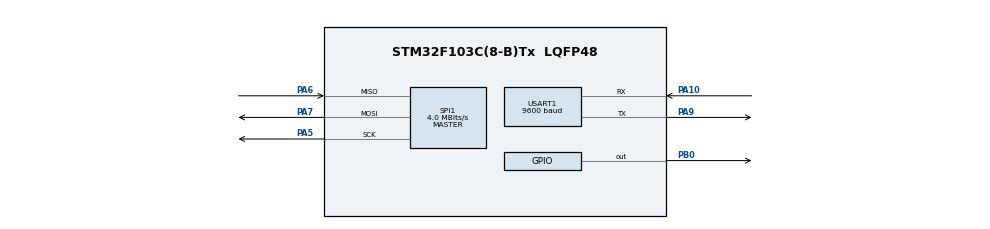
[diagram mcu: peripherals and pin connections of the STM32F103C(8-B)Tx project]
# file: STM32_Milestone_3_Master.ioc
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Mcu.Family=STM32F1
Mcu.Name=STM32F103C(8-B)Tx
Mcu.Package=LQFP48
NVIC.PriorityGroup=NVIC_PRIORITYGROUP_4
PA10.Mode=Asynchronous
PA10.Signal=USART1_RX
PA5.Mode=Full_Duplex_Master
PA5.Signal=SPI1_SCK
PA6.Mode=Full_Duplex_Master
PA6.Signal=SPI1_MISO
PA7.Mode=Full_Duplex_Master
PA7.Signal=SPI1_MOSI
PA9.Mode=Asynchronous
PA9.Signal=USART1_TX
PB0.Signal=GPIO_Output
ProjectManager.HeapSize=0x200
ProjectManager.StackSize=0x400
ProjectManager.TargetToolchain=STM32CubeIDE
RCC.APB1Freq_Value=8000000
RCC.APB2Freq_Value=8000000
SPI1.CalculateBaudRate=4.0 MBits/s
SPI1.Direction=SPI_DIRECTION_2LINES
SPI1.Mode=SPI_MODE_MASTER
SPI1.VirtualType=VM_MASTER
USART1.BaudRate=9600
USART1.VirtualMode=VM_ASYNC
VP_SYS_VS_ND.Mode=No_Debug
board=custom

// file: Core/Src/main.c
/* USER CODE BEGIN Header */
/**
  ******************************************************************************
  * @file           : main.c
  * @brief          : Main program body
  ******************************************************************************
  * @attention
  *
  * Copyright (c) 2026 STMicroelectronics.
  * All rights reserved.
  *
  * This software is licensed under terms that can be found in the LICENSE file
  * in the root directory of this software component.
  * If no LICENSE file comes with this software, it is provided AS-IS.
  *
  ******************************************************************************
  */
/* USER CODE END Header */
#include "main.h"
#include <stdio.h>
#include <string.h>

SPI_HandleTypeDef hspi1;

UART_HandleTypeDef huart1;

/* USER CODE BEGIN PV */
uint8_t rx_byte;
uint8_t case_number;
uint16_t case_id;

uint8_t tx_id[2];
uint8_t dummy_rx_id[2];      /* discarded bytes echoed by Slave during Cycle 1 */

uint8_t dummy_tx[3] = {0x00, 0x00, 0x00};
uint8_t rx_data[3];

uint16_t voltage_x10;
uint16_t wheel_speed;

char message[100];
/* USER CODE END PV */

void SystemClock_Config(void);
static void MX_GPIO_Init(void);
static void MX_SPI1_Init(void);
static void MX_USART1_UART_Init(void);

int main(void)
{

  /* MCU Configuration--------------------------------------------------------*/

  /* Reset of all peripherals, Initializes the Flash interface and the Systick. */
  HAL_Init();

  /* Configure the system clock */
  SystemClock_Config();

  /* Initialize all configured peripherals */
  MX_GPIO_Init();
  MX_SPI1_Init();
  MX_USART1_UART_Init();
  /* USER CODE BEGIN 2 */
  HAL_GPIO_WritePin(GPIOB, GPIO_PIN_0, GPIO_PIN_SET);
  /* USER CODE END 2 */

  /* Infinite loop */
  /* USER CODE BEGIN WHILE */
  while (1)
  {
      /* Ask user for Case ID */
      char prompt[] = "Enter Case ID (1-5):\r\n";

      HAL_UART_Transmit(
          &huart1,
          (uint8_t *)prompt,
          strlen(prompt),
          HAL_MAX_DELAY
      );

      /* Wait for one character from Virtual Terminal */
      HAL_UART_Receive(
          &huart1,
          &rx_byte,
          1,
          HAL_MAX_DELAY
      );

      if (rx_byte >= '1' && rx_byte <= '5')
      {
          case_number = rx_byte - '0';
          case_id = 0x1000 + case_number;

          tx_id[0] = (case_id >> 8) & 0xFF;
          tx_id[1] = case_id & 0xFF;

          /* -------- Cycle 1: send Case ID to Slave -------- */

          HAL_GPIO_WritePin(
              GPIOB,
              GPIO_PIN_0,
              GPIO_PIN_RESET
          );

          HAL_SPI_TransmitReceive(
              &hspi1,
              tx_id,
              dummy_rx_id,
              2,
              HAL_MAX_DELAY
          );

          HAL_Delay(2);

          /* -------- Cycle 2: receive 24-bit response from Slave -------- */

          HAL_SPI_TransmitReceive(
              &hspi1,
              dummy_tx,
              rx_data,
              3,
              HAL_MAX_DELAY
          );

          HAL_GPIO_WritePin(
              GPIOB,
              GPIO_PIN_0,
              GPIO_PIN_SET
          );

          uint32_t received_message =
              ((uint32_t)rx_data[0] << 16) |
              ((uint32_t)rx_data[1] << 8) |
              rx_data[2];

          voltage_x10 =
              (received_message >> 12) & 0xFFF;

          wheel_speed =
              received_message & 0xFFF;
          sprintf(message, "RAW: %02X %02X %02X\r\n", rx_data[0], rx_data[1], rx_data[2]);
          HAL_UART_Transmit(&huart1, (uint8_t*)message, strlen(message), HAL_MAX_DELAY);
          sprintf(
              message,
              "Case %d -> Voltage = %u.%u V | Wheel Speed = %u km/h\r\n",
              case_number,
              voltage_x10 / 10,
              voltage_x10 % 10,
              wheel_speed
          );

          HAL_UART_Transmit(
              &huart1,
              (uint8_t *)message,
              strlen(message),
              HAL_MAX_DELAY
          );
      }
  }
  /* USER CODE END 3 */
}

void SystemClock_Config(void)
{
  RCC_OscInitTypeDef RCC_OscInitStruct = {0};
  RCC_ClkInitTypeDef RCC_ClkInitStruct = {0};

  RCC_OscInitStruct.OscillatorType = RCC_OSCILLATORTYPE_HSI;
  RCC_OscInitStruct.HSIState = RCC_HSI_ON;
  RCC_OscInitStruct.HSICalibrationValue = RCC_HSICALIBRATION_DEFAULT;
  RCC_OscInitStruct.PLL.PLLState = RCC_PLL_NONE;
  if (HAL_RCC_OscConfig(&RCC_OscInitStruct) != HAL_OK)
  {
    Error_Handler();
  }

  RCC_ClkInitStruct.ClockType = RCC_CLOCKTYPE_HCLK|RCC_CLOCKTYPE_SYSCLK
                              |RCC_CLOCKTYPE_PCLK1|RCC_CLOCKTYPE_PCLK2;
  RCC_ClkInitStruct.SYSCLKSource = RCC_SYSCLKSOURCE_HSI;
  RCC_ClkInitStruct.AHBCLKDivider = RCC_SYSCLK_DIV1;
  RCC_ClkInitStruct.APB1CLKDivider = RCC_HCLK_DIV1;
  RCC_ClkInitStruct.APB2CLKDivider = RCC_HCLK_DIV1;

  if (HAL_RCC_ClockConfig(&RCC_ClkInitStruct, FLASH_LATENCY_0) != HAL_OK)
  {
    Error_Handler();
  }
}

static void MX_SPI1_Init(void)
{

  /* SPI1 parameter configuration*/
  hspi1.Instance = SPI1;
  hspi1.Init.Mode = SPI_MODE_MASTER;
  hspi1.Init.Direction = SPI_DIRECTION_2LINES;
  hspi1.Init.DataSize = SPI_DATASIZE_8BIT;
  hspi1.Init.CLKPolarity = SPI_POLARITY_LOW;
  hspi1.Init.CLKPhase = SPI_PHASE_1EDGE;
  hspi1.Init.NSS = SPI_NSS_SOFT;
  hspi1.Init.BaudRatePrescaler = SPI_BAUDRATEPRESCALER_256;
  hspi1.Init.FirstBit = SPI_FIRSTBIT_MSB;
  hspi1.Init.TIMode = SPI_TIMODE_DISABLE;
  hspi1.Init.CRCCalculation = SPI_CRCCALCULATION_DISABLE;
  hspi1.Init.CRCPolynomial = 10;
  if (HAL_SPI_Init(&hspi1) != HAL_OK)
  {
    Error_Handler();
  }

}

static void MX_USART1_UART_Init(void)
{

  huart1.Instance = USART1;
  huart1.Init.BaudRate = 9600;
  huart1.Init.WordLength = UART_WORDLENGTH_8B;
  huart1.Init.StopBits = UART_STOPBITS_1;
  huart1.Init.Parity = UART_PARITY_NONE;
  huart1.Init.Mode = UART_MODE_TX_RX;
  huart1.Init.HwFlowCtl = UART_HWCONTROL_NONE;
  huart1.Init.OverSampling = UART_OVERSAMPLING_16;
  if (HAL_UART_Init(&huart1) != HAL_OK)
  {
    Error_Handler();
  }

}

static void MX_GPIO_Init(void)
{
  GPIO_InitTypeDef GPIO_InitStruct = {0};

  /* GPIO Ports Clock Enable */
  __HAL_RCC_GPIOA_CLK_ENABLE();
  __HAL_RCC_GPIOB_CLK_ENABLE();

  /*Configure GPIO pin Output Level */
  HAL_GPIO_WritePin(GPIOB, GPIO_PIN_0, GPIO_PIN_RESET);

  /*Configure GPIO pin : PB0 */
  GPIO_InitStruct.Pin = GPIO_PIN_0;
  GPIO_InitStruct.Mode = GPIO_MODE_OUTPUT_PP;
  GPIO_InitStruct.Pull = GPIO_NOPULL;
  GPIO_InitStruct.Speed = GPIO_SPEED_FREQ_LOW;
  HAL_GPIO_Init(GPIOB, &GPIO_InitStruct);

}

void Error_Handler(void)
{
  __disable_irq();
  while (1)
  {
  }
}
